# APM32F411 register map
Vendor: Geehy; File version: 2024.11.05
CPU: CM4 r1p0, little endian, 3 interrupt priority bits
Registers are 32-bit, read-write, reset 0x0 unless marked. A register's access mark holds for its fields unless they carry their own. Offsets are from the block's base; [hi:lo] are bit positions; {n}, {i} and the like mark numbered series.

## COMP1 — Comparator
Base 0x40013818
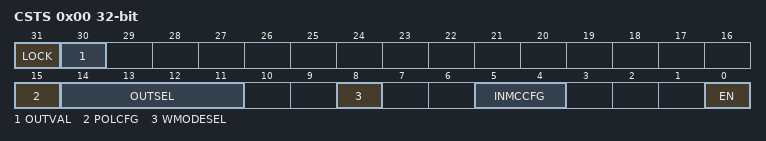
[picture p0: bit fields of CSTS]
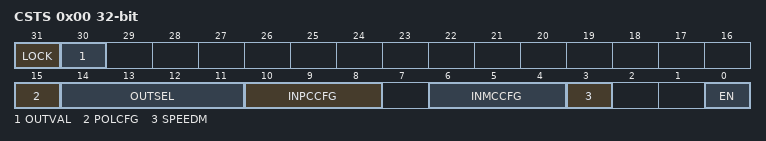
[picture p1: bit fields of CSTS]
0x00 CSTS — control and status register
  [31] LOCK — COMP CSTS Register Lock
  [30] OUTVAL — Comparator 1 output status
  [15] POLCFG — Comparator 1 Polarity Configure
  [14:11] OUTSEL — Comparator 1 output Selest
  [8] WMODESEL — Comparator 1 Window Mode Select
  [5:4] INMCCFG — Comparator 1 Input Minus Connection Configure
  [0] EN — Comparator 1 enable

## COMP2 — Comparator
Base 0x4001381C
0x00 CSTS — control and status register
  [31] LOCK — COMP CSTS Register Lock
  [30] OUTVAL — Comparator output status
  [15] POLCFG — Comparator Polarity Configure
  [14:11] OUTSEL — Comparator output Selest
  [10:8] INPCCFG — Comparator Input Plus Connection Configure
  [6:4] INMCCFG — Comparator Input Minus Connection Configure
  [3] SPEEDM — Comparator Speed Mode Select
  [0] EN — Comparator enable

## CRC — Cryptographic processor
Base 0x40023000
0x00 DATA reset 0xFFFFFFFF
0x04 INDATA — Independent Data register
  [7:0] INDATA
0x08 CTRL wo — Control register
  [0] RST — Reset CRC Calculation Unit

## DBGMCU — Debug support
Base 0xE0042000
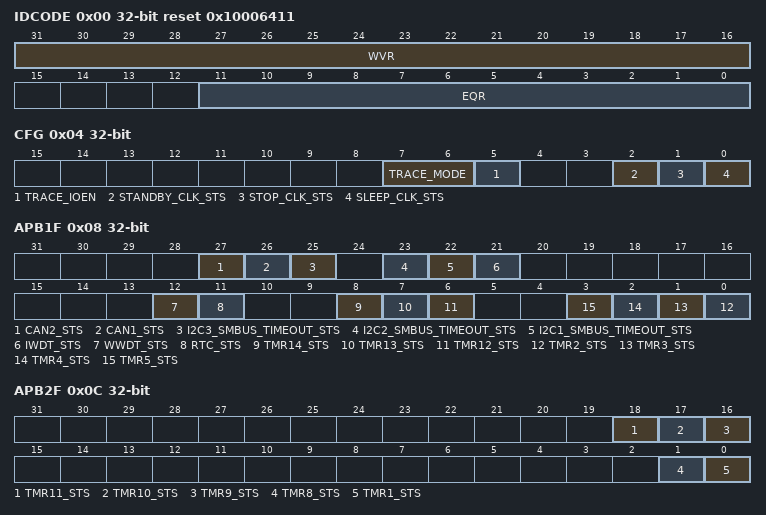
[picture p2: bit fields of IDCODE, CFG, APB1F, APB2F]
0x00 IDCODE ro reset 0x10006411
  [31:16] WVR — Wafer Version Recognition
  [11:0] EQR — Equipment Recognition
0x04 CFG — Control Register
  [7:6] TRACE_MODE — Trace Debug Pin Mode Configure
  [5] TRACE_IOEN — Trace Debug Pin Enable
  [2] STANDBY_CLK_STS — Configure clock status when MCU is debugged in standby mode
  [1] STOP_CLK_STS — Configure clock status when MCU is debugged in stop mode
  [0] SLEEP_CLK_STS — Configure clock status when MCU is debugged in sleep mode
0x08 APB1F — Debug MCU APB1 Freeze registe
  [27] CAN2_STS — CAN2 counter stopped when core is halted
  [26] CAN1_STS — CAN1 counter stopped when core is halted
  [25] I2C3_SMBUS_TIMEOUT_STS
  [23] I2C2_SMBUS_TIMEOUT_STS
  [22] I2C1_SMBUS_TIMEOUT_STS
  [21] IWDT_STS — IWDT counter stopped when core is halted
  [12] WWDT_STS — WWDT counter stopped when core is halted
  [11] RTC_STS — RTC counter stopped when core is halted
  [8] TMR14_STS — TMR14 counter stopped when core is halted
  [7] TMR13_STS — TMR13 counter stopped when core is halted
  [6] TMR12_STS — TMR12 counter stopped when core is halted
  [n-2] TMR{n}_STS (n=2..5) — TMR{n} counter stopped when core is halted
0x0C APB2F — Debug MCU APB2 Freeze registe
  [18] TMR11_STS — TMR11 counter stopped when core is halted
  [17] TMR10_STS — TMR10 counter stopped when core is halted
  [16] TMR9_STS — TMR9 counter stopped when core is halted
  [1] TMR8_STS — TMR8 counter stopped when core is halted
  [0] TMR1_STS — TMR1 counter stopped when core is halted

## EINT — External interrupt/event controller
Base 0x40013C00
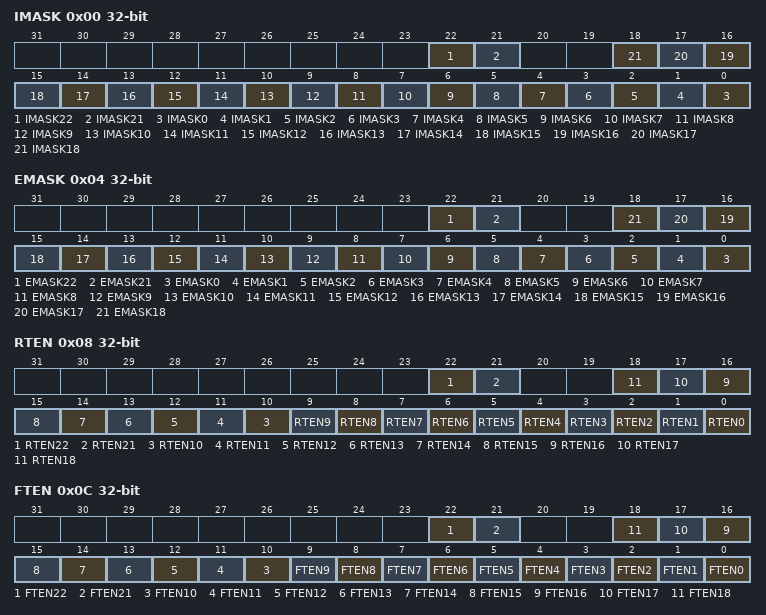
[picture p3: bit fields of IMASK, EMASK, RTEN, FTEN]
0x00 IMASK — Interrupt mask register
  [22] IMASK22 — Interrupt Mask on line 22
  [21] IMASK21 — Interrupt Mask on line 21
  [n] IMASK{n} (n=0..18) — Interrupt Mask on line {n}
0x04 EMASK — Event mask register
  [22] EMASK22 — Event Mask on line 22
  [21] EMASK21 — Event Mask on line 21
  [n] EMASK{n} (n=0..18) — Event Mask on line {n}
0x08 RTEN — Rising Trigger selection register
  [22] RTEN22 — Rising trigger event configuration of line 22
  [21] RTEN21 — Rising trigger event configuration of line 21
  [n] RTEN{n} (n=0..18) — Rising trigger event configuration of line {n}
0x0C FTEN — Falling Trigger selection register
  [22] FTEN22 — Falling trigger event configuration of line 22
  [21] FTEN21 — Falling trigger event configuration of line 21
  [n] FTEN{n} (n=0..18) — Falling trigger event configuration of line {n}
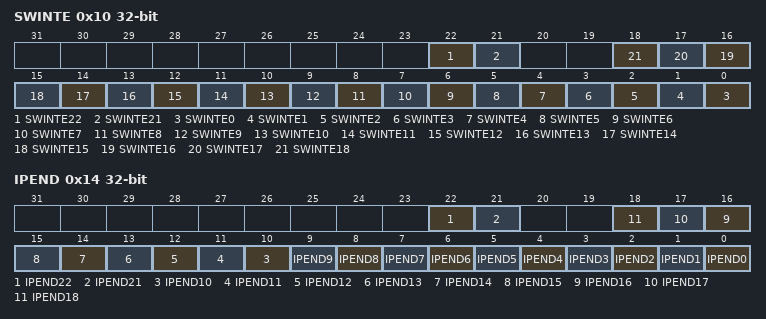
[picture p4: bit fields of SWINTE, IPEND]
0x10 SWINTE — Software interrupt event register
  [22] SWINTE22 — Software Interrupt on line 22
  [21] SWINTE21 — Software Interrupt on line 21
  [n] SWINTE{n} (n=0..18) — Software Interrupt on line {n}
0x14 IPEND — Pending register
  [22] IPEND22 — Pending bit 22
  [21] IPEND21 — Pending bit 21
  [n] IPEND{n} (n=0..18) — Pending bit {n}
